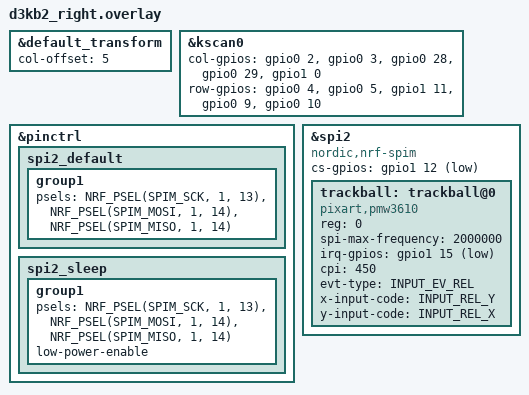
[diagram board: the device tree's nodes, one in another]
#include <zephyr/dt-bindings/input/input-event-codes.h>
#include "d3kb2.dtsi"

&default_transform {
    col-offset = <5>;
};

&kscan0{
    col-gpios
        = <&gpio0  2 GPIO_ACTIVE_HIGH>
        , <&gpio0  3 GPIO_ACTIVE_HIGH>
        , <&gpio0 28 GPIO_ACTIVE_HIGH>
        , <&gpio0 29 GPIO_ACTIVE_HIGH>
        , <&gpio1  0 GPIO_ACTIVE_HIGH>
        ; 
    row-gpios
        = <&gpio0  4 (GPIO_ACTIVE_HIGH | GPIO_PULL_DOWN)>
        , <&gpio0  5 (GPIO_ACTIVE_HIGH | GPIO_PULL_DOWN)>
        , <&gpio1 11 (GPIO_ACTIVE_HIGH | GPIO_PULL_DOWN)>
        , <&gpio0  9 (GPIO_ACTIVE_HIGH | GPIO_PULL_DOWN)>
        , <&gpio0 10 (GPIO_ACTIVE_HIGH | GPIO_PULL_DOWN)>
        ;
};



&pinctrl {
    spi2_default: spi2_default {
		group1 {
			psels = <NRF_PSEL(SPIM_SCK, 1, 13)>,
				<NRF_PSEL(SPIM_MOSI, 1, 14)>,
				<NRF_PSEL(SPIM_MISO, 1, 14)>;
		};
    };
    spi2_sleep: spi2_sleep {
        group1 {
			psels = <NRF_PSEL(SPIM_SCK, 1, 13)>,
				<NRF_PSEL(SPIM_MOSI, 1, 14)>,
				<NRF_PSEL(SPIM_MISO, 1, 14)>;
			low-power-enable;
		};
    };
};


&spi2 {
    status = "okay";
    compatible = "nordic,nrf-spim";
    cs-gpios = <&gpio1 12 GPIO_ACTIVE_LOW>;

    trackball: trackball@0 {
        status = "okay";
        compatible = "pixart,pmw3610";
        reg = <0>;
        spi-max-frequency = <2000000>;
        irq-gpios = <&gpio1 15 (GPIO_ACTIVE_LOW | GPIO_PULL_UP)>;

        cpi = <450>;
        evt-type = <INPUT_EV_REL>;
        x-input-code = <INPUT_REL_Y>;
        y-input-code = <INPUT_REL_X>;
    };
};
